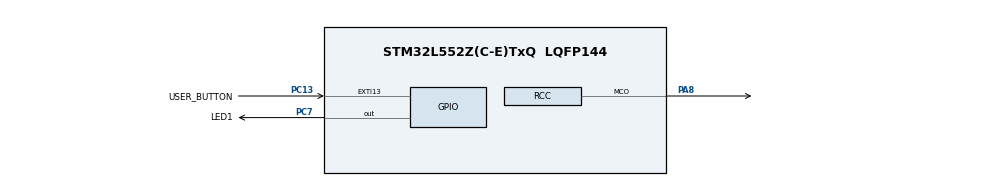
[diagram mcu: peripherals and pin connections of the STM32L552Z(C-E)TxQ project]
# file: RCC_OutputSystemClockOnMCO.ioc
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Mcu.Family=STM32L5
Mcu.Name=STM32L552Z(C-E)TxQ
Mcu.Package=LQFP144
Mcu.TrustZone=disable
NVIC.EXTI13_IRQn=true\:3\:0\:true\:false\:true\:true\:true\:true
NVIC.PriorityGroup=NVIC_PRIORITYGROUP_3
PA8.GPIO_PuPd=GPIO_NOPULL
PA8.GPIO_Speed=GPIO_SPEED_FREQ_HIGH
PA8.Mode=Clock-out
PA8.Signal=RCC_MCO
PC13.GPIO_Label=USER_BUTTON
PC13.GPIO_ModeDefaultEXTI=GPIO_MODE_IT_FALLING
PC13.GPIO_PuPd=GPIO_PULLDOWN
PC13.Signal=GPXTI13
PC7.GPIO_Label=LED1
PC7.Signal=GPIO_Output
ProjectManager.HeapSize=0x200
ProjectManager.StackSize=0x400
ProjectManager.TargetToolchain=EWARM V8.32
RCC.ADCCLockSelection=RCC_ADCCLKSOURCE_SYSCLK
RCC.ADCFreq_Value=110000000
RCC.AHBFreq_Value=110000000
RCC.APB1Freq_Value=110000000
RCC.APB1TimFreq_Value=110000000
RCC.APB2Freq_Value=110000000
RCC.APB2TimFreq_Value=110000000
RCC.CortexFreq_Value=110000000
RCC.HCLKFreq_Value=110000000
RCC.HSE_VALUE=16000000
RCC.HSI48_VALUE=48000000
RCC.HSI_VALUE=16000000
RCC.LSE_VALUE=32768
RCC.MSI_VALUE=4000000
RCC.PLLN=55
RCC.PLLSAI1N=24
RCC.RTCClockSelection=RCC_RTCCLKSOURCE_LSE
RCC.SYSCLKFreq_VALUE=110000000
RCC.SYSCLKSource=RCC_SYSCLKSOURCE_PLLCLK
RCC.USBFreq_Value=48000000
RCC.VCOOutputFreq_Value=220000000
VP_ICACHE_VS_ICACHE.Mode=DirectMappedCache
VP_PWR_VS_DBSignals.Mode=DisableDeadBatterySignals
board=custom

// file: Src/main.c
/* USER CODE BEGIN Header */
/**
  ******************************************************************************
  * @file    Examples_LL/RCC/RCC_OutputSystemClockOnMCO/Src/main.c
  * @author  MCD Application Team
  * @brief   This example describes how to how to configure MCO pin to output
  *          the system clock through the STM32L5xx RCC LL API.
  ******************************************************************************
  * @attention
  *
  * Copyright (c) 2019 STMicroelectronics.
  * All rights reserved.
  *
  * This software is licensed under terms that can be found in the LICENSE file
  * in the root directory of this software component.
  * If no LICENSE file comes with this software, it is provided AS-IS.
  *
  ******************************************************************************
  */
/* USER CODE END Header */
#include "main.h"

/* USER CODE BEGIN PTD */
/* Structure based on parameters used for MCO config */
typedef struct
{
  uint32_t Source;          /*!< Source of the MCO output */
  uint32_t Prescaler;       /*!< Prescaler applied to MCO output */
} RCC_MCO_ConfigTypeDef;

__IO uint8_t ubButtonPress = 0;
/* USER CODE END PTD */

/* USER CODE BEGIN PD */

/* Number of MCO Config */
#define RCC_MCO_CONFIG_NB   3

/* USER CODE END PD */

/* USER CODE BEGIN PV */

/* Variable to set different MCO config */
static RCC_MCO_ConfigTypeDef aMCO_Config[RCC_MCO_CONFIG_NB] =
{
  {LL_RCC_MCO1SOURCE_SYSCLK, LL_RCC_MCO1_DIV_1},
  {LL_RCC_MCO1SOURCE_MSI, LL_RCC_MCO1_DIV_2},
  {LL_RCC_MCO1SOURCE_PLLCLK, LL_RCC_MCO1_DIV_4},
};

/* MCO Config index */
__IO uint8_t bMCOIndex = 1;

/* USER CODE END PV */

void SystemClock_Config(void);
static void MX_GPIO_Init(void);
static void MX_ICACHE_Init(void);

int main(void)
{

  /* MCU Configuration--------------------------------------------------------*/

  /* Reset of all peripherals, Initializes the Flash interface and the Systick. */
  LL_APB2_GRP1_EnableClock(LL_APB2_GRP1_PERIPH_SYSCFG);
  LL_APB1_GRP1_EnableClock(LL_APB1_GRP1_PERIPH_PWR);

  /* System interrupt init*/
  NVIC_SetPriorityGrouping(NVIC_PRIORITYGROUP_3);

  /** Disable the internal Pull-Up in Dead Battery pins of UCPD peripheral
  */
  LL_PWR_DisableUCPDDeadBattery();

  /* Configure the system clock */
  SystemClock_Config();

  /* Initialize all configured peripherals */
  MX_GPIO_Init();
  MX_ICACHE_Init();

  /* Infinite loop */
  while (1)
  {

    /* USER CODE BEGIN 3 */
    /* All the process are managed in UserButton_Callback function */
    /* Each time, user press user-button, a new MCO config is set */

  }
  /* USER CODE END 3 */
}

void SystemClock_Config(void)
{
  LL_FLASH_SetLatency(LL_FLASH_LATENCY_5);
  while(LL_FLASH_GetLatency()!= LL_FLASH_LATENCY_5)
  {
  }

  LL_PWR_SetRegulVoltageScaling(LL_PWR_REGU_VOLTAGE_SCALE0);
  LL_RCC_MSI_Enable();

   /* Wait till MSI is ready */
  while(LL_RCC_MSI_IsReady() != 1)
  {
  }

  LL_RCC_MSI_EnableRangeSelection();
  LL_RCC_MSI_SetRange(LL_RCC_MSIRANGE_6);
  LL_RCC_MSI_SetCalibTrimming(0);
  LL_RCC_PLL_ConfigDomain_SYS(LL_RCC_PLLSOURCE_MSI, LL_RCC_PLLM_DIV_1, 55, LL_RCC_PLLR_DIV_2);
  LL_RCC_PLL_EnableDomain_SYS();
  LL_RCC_PLL_Enable();

   /* Wait till PLL is ready */
  while(LL_RCC_PLL_IsReady() != 1)
  {
  }

   /* Intermediate AHB prescaler 2 when target frequency clock is higher than 80 MHz */
   LL_RCC_SetAHBPrescaler(LL_RCC_SYSCLK_DIV_2);

  LL_RCC_SetSysClkSource(LL_RCC_SYS_CLKSOURCE_PLL);

   /* Wait till System clock is ready */
  while(LL_RCC_GetSysClkSource() != LL_RCC_SYS_CLKSOURCE_STATUS_PLL)
  {
  }

  /* Insure 1us transition state at intermediate medium speed clock*/
  for (__IO uint32_t i = (RCC_MAX_FREQUENCY_MHZ >> 1); i !=0; i--);

  LL_RCC_SetAHBPrescaler(LL_RCC_SYSCLK_DIV_1);
  LL_RCC_SetAPB1Prescaler(LL_RCC_APB1_DIV_1);
  LL_RCC_SetAPB2Prescaler(LL_RCC_APB2_DIV_1);

  LL_Init1msTick(110000000);

  LL_SetSystemCoreClock(110000000);
  LL_RCC_ConfigMCO(LL_RCC_MCO1SOURCE_SYSCLK, LL_RCC_MCO1_DIV_1);
}

static void MX_ICACHE_Init(void)
{

  /** Enable instruction cache in 1-way (direct mapped cache)
  */
  LL_ICACHE_SetMode(LL_ICACHE_1WAY);
  LL_ICACHE_Enable();

}

static void MX_GPIO_Init(void)
{
  LL_EXTI_InitTypeDef EXTI_InitStruct = {0};
  LL_GPIO_InitTypeDef GPIO_InitStruct = {0};

  /* GPIO Ports Clock Enable */
  LL_AHB2_GRP1_EnableClock(LL_AHB2_GRP1_PERIPH_GPIOC);
  LL_AHB2_GRP1_EnableClock(LL_AHB2_GRP1_PERIPH_GPIOA);

  /**/
  LL_GPIO_ResetOutputPin(LED1_GPIO_Port, LED1_Pin);

  /**/
  LL_EXTI_SetEXTISource(LL_EXTI_EXTI_PORTC, LL_EXTI_EXTI_LINE13);

  /**/
  EXTI_InitStruct.Line_0_31 = LL_EXTI_LINE_13;
  EXTI_InitStruct.Line_32_63 = LL_EXTI_LINE_NONE;
  EXTI_InitStruct.LineCommand = ENABLE;
  EXTI_InitStruct.Mode = LL_EXTI_MODE_IT;
  EXTI_InitStruct.Trigger = LL_EXTI_TRIGGER_FALLING;
  LL_EXTI_Init(&EXTI_InitStruct);

  /**/
  LL_GPIO_SetPinPull(USER_BUTTON_GPIO_Port, USER_BUTTON_Pin, LL_GPIO_PULL_DOWN);

  /**/
  LL_GPIO_SetPinMode(USER_BUTTON_GPIO_Port, USER_BUTTON_Pin, LL_GPIO_MODE_INPUT);

  /**/
  GPIO_InitStruct.Pin = LED1_Pin;
  GPIO_InitStruct.Mode = LL_GPIO_MODE_OUTPUT;
  GPIO_InitStruct.Speed = LL_GPIO_SPEED_FREQ_LOW;
  GPIO_InitStruct.OutputType = LL_GPIO_OUTPUT_PUSHPULL;
  GPIO_InitStruct.Pull = LL_GPIO_PULL_NO;
  LL_GPIO_Init(LED1_GPIO_Port, &GPIO_InitStruct);

  /**/
  GPIO_InitStruct.Pin = LL_GPIO_PIN_8;
  GPIO_InitStruct.Mode = LL_GPIO_MODE_ALTERNATE;
  GPIO_InitStruct.Speed = LL_GPIO_SPEED_FREQ_HIGH;
  GPIO_InitStruct.OutputType = LL_GPIO_OUTPUT_PUSHPULL;
  GPIO_InitStruct.Pull = LL_GPIO_PULL_NO;
  GPIO_InitStruct.Alternate = LL_GPIO_AF_0;
  LL_GPIO_Init(GPIOA, &GPIO_InitStruct);

  /* EXTI interrupt init*/
  NVIC_SetPriority(EXTI13_IRQn, NVIC_EncodePriority(NVIC_GetPriorityGrouping(),3, 0));
  NVIC_EnableIRQ(EXTI13_IRQn);

}

/* USER CODE BEGIN 4 */

/******************************************************************************/
/*   USER IRQ HANDLER TREATMENT                                               */
/******************************************************************************/
/**
  * @brief  Function to manage User button press
  * @param  None
  * @retval None
  */
void UserButton_Callback(void)
{
  register uint32_t source = 0, prescaler = 0;

  /* Get the MCO config to apply */
  source = aMCO_Config[bMCOIndex].Source;
  prescaler = aMCO_Config[bMCOIndex].Prescaler;

  /* Toggle LED1 to indicate a button press*/
  LL_GPIO_TogglePin(LED1_GPIO_Port, LED1_Pin);
  ubButtonPress = 1;

  /* Select MCO clock source and prescaler */
  LL_RCC_ConfigMCO(source, prescaler);

  /* Set new MCO config Index */
  bMCOIndex = (bMCOIndex + 1) % RCC_MCO_CONFIG_NB;
}

/* USER CODE END 4 */

void Error_Handler(void)
{
  while(1)
  {
  }
}
